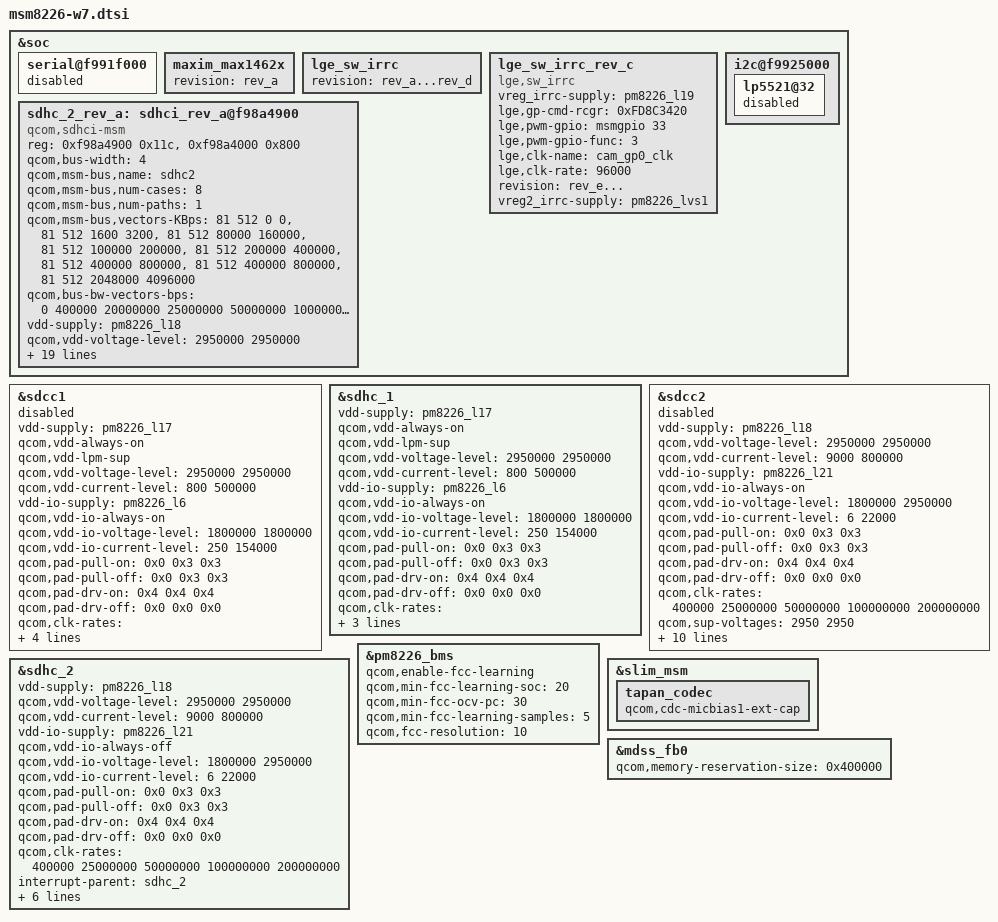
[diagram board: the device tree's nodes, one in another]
/* Copyright (c) 2012, Code Aurora Forum. All rights reserved.
 *
 * This program is free software; you can redistribute it and/or modify
 * it under the terms of the GNU General Public License version 2 and
 * only version 2 as published by the Free Software Foundation.
 *
 * This program is distributed in the hope that it will be useful,
 * but WITHOUT ANY WARRANTY; without even the implied warranty of
 * MERCHANTABILITY or FITNESS FOR A PARTICULAR PURPOSE.  See the
 * GNU General Public License for more details.
 */

/include/ "msm8226-w7-panel.dtsi"
/include/ "msm8226-w7-sensor.dtsi"
/include/ "msm8226-w7-hdmi.dtsi"
/include/ "msm8226-w7-usb.dtsi"
/include/ "msm8226-w7-misc.dtsi"
/include/ "msm8226-w7-pm.dtsi"
/include/ "msm8226-w7-camera.dtsi"
/include/ "msm8226-w7-input.dtsi"
/include/ "msm8226-w7-nfc.dtsi"

&soc {
	serial@f991f000 {
		status = "disabled";
	};

	maxim_max1462x { //LGE_UPDATE 20130626 beekay.lee@lge.com WX_MAXIM
		status = "ok";          //"ok" or "disable"
		revision = "rev_a";
	};

	lge_sw_irrc { /* LGE_UPDATE 20130626 beekay.lee@lge.com WX_IRRC */
                     status = "ok";
                     revision = "rev_a...rev_d";
           };

	lge_sw_irrc_rev_c { /* LGE_UPDATE 20130626 beekay.lee@lge.com WX_IRRC */
                     compatible = "lge,sw_irrc";
                     vreg_irrc-supply = <&pm8226_l19>;
                     lge,gp-cmd-rcgr = <0xFD8C3420>;
                     lge,pwm-gpio = <&msmgpio 33 0x00>;
                     lge,pwm-gpio-func = <3>;
                     lge,clk-name = "cam_gp0_clk";
                     lge,clk-rate = <96000>; //This must match with clk_freq_tbl.

                     status = "ok";
                     revision = "rev_e...";
                     vreg2_irrc-supply = <&pm8226_lvs1>;
           };

	i2c@f9925000 {
		lp5521@32 {
			status = "disable";
		};
	};
	/* Rev.a ...*/
	sdhc_2_rev_a: sdhci_rev_a@f98a4900 {
		compatible = "qcom,sdhci-msm";
		reg = <0xf98a4900 0x11c>, <0xf98a4000 0x800>;
		reg-names = "hc_mem", "core_mem";

		qcom,bus-width = <4>;
		qcom,msm-bus,name = "sdhc2";
		qcom,msm-bus,num-cases = <8>;
		qcom,msm-bus,num-paths = <1>;
		qcom,msm-bus,vectors-KBps = <81 512 0 0>, /* No vote */
						<81 512 1600 3200>,    /* 400 KB/s*/
						<81 512 80000 160000>, /* 20 MB/s */
						<81 512 100000 200000>, /* 25 MB/s */
						<81 512 200000 400000>, /* 50 MB/s */
						<81 512 400000 800000>, /* 100 MB/s */
						<81 512 400000 800000>, /* 200 MB/s */
						<81 512 2048000 4096000>; /* Max. bandwidth */
		qcom,bus-bw-vectors-bps = <0 400000 20000000 25000000 50000000
										100000000 200000000 4294967295>;

		vdd-supply = <&pm8226_l18>;
		qcom,vdd-voltage-level = <2950000 2950000>;
		qcom,vdd-current-level = <9000 800000>;

		vdd-io-supply = <&pm8226_l21>;
		qcom,vdd-io-always-on;
		qcom,vdd-io-lpm-sup;
		qcom,vdd-io-voltage-level = <1800000 2950000>;
		qcom,vdd-io-current-level = <6 22000>;

		qcom,pad-pull-on = <0x0 0x3 0x3>; /* no-pull, pull-up, pull-up */
		qcom,pad-pull-off = <0x0 0x3 0x3>; /* no-pull, pull-up, pull-up */
		qcom,pad-drv-on = <0x4 0x4 0x4>; /* 10mA, 10mA, 10mA */
		qcom,pad-drv-off = <0x0 0x0 0x0>; /* 2mA, 2mA, 2mA */

		qcom,clk-rates = <400000 25000000 50000000 100000000 200000000>;

		#address-cells = <0>;
		interrupt-parent = <&sdhc_2_rev_a>;
		interrupts = <0 1 2>;
		#interrupt-cells = <1>;
		interrupt-map-mask = <0xffffffff>;
		interrupt-map = <0 &intc 0 125 0
						1 &intc 0 221 0
						2 &msmgpio 37 0x3>;
		interrupt-names = "hc_irq", "pwr_irq", "status_irq";
		cd-gpios = <&msmgpio 37 0x1>;

		revision = "...rev_a";

		status = "ok";
};
};

&sdcc1 {
	vdd-supply = <&pm8226_l17>;
	qcom,vdd-always-on;
	qcom,vdd-lpm-sup;
	qcom,vdd-voltage-level = <2950000 2950000>;
	qcom,vdd-current-level = <800 500000>;

	vdd-io-supply = <&pm8226_l6>;
	qcom,vdd-io-always-on;
	qcom,vdd-io-voltage-level = <1800000 1800000>;
	qcom,vdd-io-current-level = <250 154000>;

	qcom,pad-pull-on = <0x0 0x3 0x3>; /* no-pull, pull-up, pull-up */
	qcom,pad-pull-off = <0x0 0x3 0x3>; /* no-pull, pull-up, pull-up */
	qcom,pad-drv-on = <0x4 0x4 0x4>; /* 10mA, 10mA, 10mA */
	qcom,pad-drv-off = <0x0 0x0 0x0>; /* 2mA, 2mA, 2mA */

	qcom,clk-rates = <400000 25000000 50000000 100000000 200000000>;
	qcom,sup-voltages = <2950 2950>;

	qcom,bus-speed-mode = "HS200_1p8v", "DDR_1p8v";
	qcom,nonremovable;

   status = "disabled";
};

&sdhc_1 {
   vdd-supply = <&pm8226_l17>;
   qcom,vdd-always-on;
   qcom,vdd-lpm-sup;
   qcom,vdd-voltage-level = <2950000 2950000>;
   qcom,vdd-current-level = <800 500000>;

   vdd-io-supply = <&pm8226_l6>;
   qcom,vdd-io-always-on;
   qcom,vdd-io-voltage-level = <1800000 1800000>;
   qcom,vdd-io-current-level = <250 154000>;

   qcom,pad-pull-on = <0x0 0x3 0x3>; /* no-pull, pull-up, pull-up */
   qcom,pad-pull-off = <0x0 0x3 0x3>; /* no-pull, pull-up, pull-up */
   qcom,pad-drv-on = <0x4 0x4 0x4>; /* 10mA, 10mA, 10mA */
   qcom,pad-drv-off = <0x0 0x0 0x0>; /* 2mA, 2mA, 2mA */

   qcom,clk-rates = <400000 25000000 50000000 100000000 200000000>;
   qcom,bus-speed-mode = "HS200_1p8v", "DDR_1p8v";
   qcom,nonremovable;

	status = "ok";
};

&sdcc2 {
	vdd-supply = <&pm8226_l18>;
	qcom,vdd-voltage-level = <2950000 2950000>;
	qcom,vdd-current-level = <9000 800000>;

	vdd-io-supply = <&pm8226_l21>;
	qcom,vdd-io-always-on;
	qcom,vdd-io-voltage-level = <1800000 2950000>;
	qcom,vdd-io-current-level = <6 22000>;

	qcom,pad-pull-on = <0x0 0x3 0x3>; /* no-pull, pull-up, pull-up */
	qcom,pad-pull-off = <0x0 0x3 0x3>; /* no-pull, pull-up, pull-up */
	qcom,pad-drv-on = <0x4 0x4 0x4>; /* 10mA, 10mA, 10mA */
	qcom,pad-drv-off = <0x0 0x0 0x0>; /* 2mA, 2mA, 2mA */

	qcom,clk-rates = <400000 25000000 50000000 100000000 200000000>;
	qcom,sup-voltages = <2950 2950>;

	qcom,xpc;
	qcom,bus-speed-mode = "SDR12", "SDR25", "SDR50", "DDR50", "SDR104";
	qcom,current-limit = <600>; #address-cells = <0>; interrupt-parent = <&sdcc2>;
	interrupts = <0 1 2>;
	#interrupt-cells = <1>;
	interrupt-map-mask = <0xffffffff>;
	interrupt-map = <0 &intc 0 125 0
			1 &intc 0 220 0
			2 &msmgpio 38 0x3>;
	interrupt-names = "core_irq", "bam_irq", "status_irq";
	cd-gpios = <&msmgpio 38 0x0>; /* card detect 1:Low-Active, 0:High-Active */

   status = "disabled";
};

&sdhc_2 {
   vdd-supply = <&pm8226_l18>;
   qcom,vdd-voltage-level = <2950000 2950000>;
   qcom,vdd-current-level = <9000 800000>;

   vdd-io-supply = <&pm8226_l21>;
   qcom,vdd-io-always-off;
   qcom,vdd-io-voltage-level = <1800000 2950000>;
   qcom,vdd-io-current-level = <6 22000>;

   qcom,pad-pull-on = <0x0 0x3 0x3>; /* no-pull, pull-up, pull-up */
   qcom,pad-pull-off = <0x0 0x3 0x3>; /* no-pull, pull-up, pull-up */
   qcom,pad-drv-on = <0x4 0x4 0x4>; /* 10mA, 10mA, 10mA */
   qcom,pad-drv-off = <0x0 0x0 0x0>; /* 2mA, 2mA, 2mA */

   qcom,clk-rates = <400000 25000000 50000000 100000000 200000000>;

   #address-cells = <0>;
   interrupt-parent = <&sdhc_2>;
   interrupts = <0 1 2>;
   #interrupt-cells = <1>;
   interrupt-map-mask = <0xffffffff>;
   interrupt-map = <0 &intc 0 125 0
           1 &intc 0 221 0
           2 &msmgpio 37 0x3>;
   interrupt-names = "hc_irq", "pwr_irq", "status_irq";
   cd-gpios = <&msmgpio 37 0x0>; /* card detect 1:Low-Active, 0:High-Active  */

		revision = "rev_b...";
   status = "ok";
};

&pm8226_bms {
	status = "ok";
    qcom,enable-fcc-learning;
    qcom,min-fcc-learning-soc = <20>;
    qcom,min-fcc-ocv-pc = <30>;
    qcom,min-fcc-learning-samples = <5>;
    qcom,fcc-resolution = <10>;
};

&slim_msm {
	tapan_codec {
			qcom,cdc-micbias1-ext-cap;
	};
};

&mdss_fb0 {
	qcom,memory-reservation-size = <0x400000>; /* LGE chagne to decrease buffer size. QCT original -> 0x800000 */
};
